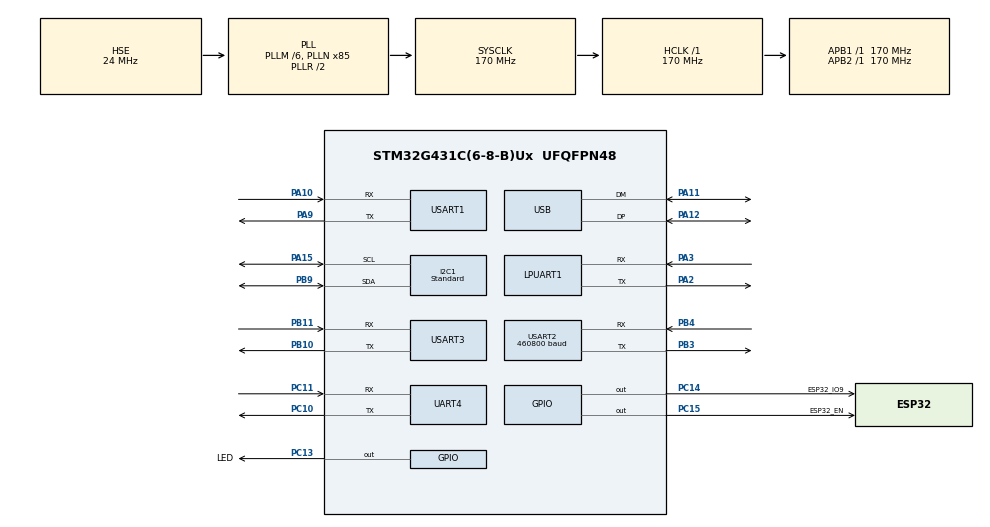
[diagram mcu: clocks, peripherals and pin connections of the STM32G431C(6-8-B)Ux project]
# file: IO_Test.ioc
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I2C1.I2C_Speed_Mode=I2C_Standard
I2C1.Timing=0x40B285C2
Mcu.Family=STM32G4
Mcu.Name=STM32G431C(6-8-B)Ux
Mcu.Package=UFQFPN48
NVIC.PriorityGroup=NVIC_PRIORITYGROUP_4
NVIC.UART4_IRQn=true\:0\:0\:false\:false\:true\:true\:true\:true
NVIC.USART2_IRQn=true\:0\:0\:false\:false\:true\:true\:true\:true
NVIC.USART3_IRQn=true\:0\:0\:false\:false\:true\:true\:true\:true
NVIC.USB_LP_IRQn=true\:0\:0\:false\:false\:true\:false\:true\:true
PA10.Mode=Asynchronous
PA10.Signal=USART1_RX
PA11.Mode=Device
PA11.Signal=USB_DM
PA12.Mode=Device
PA12.Signal=USB_DP
PA13.Mode=Serial_Wire
PA13.Signal=SYS_JTMS-SWDIO
PA14.Mode=Serial_Wire
PA14.Signal=SYS_JTCK-SWCLK
PA15.Mode=I2C
PA15.Signal=I2C1_SCL
PA2.Mode=Asynchronous
PA2.Signal=LPUART1_TX
PA3.Mode=Asynchronous
PA3.Signal=LPUART1_RX
PA9.Mode=Asynchronous
PA9.Signal=USART1_TX
PB10.Mode=Asynchronous
PB10.Signal=USART3_TX
PB11.Mode=Asynchronous
PB11.Signal=USART3_RX
PB3.Mode=Asynchronous
PB3.Signal=USART2_TX
PB4.Mode=Asynchronous
PB4.Signal=USART2_RX
PB9.Mode=I2C
PB9.Signal=I2C1_SDA
PC10.Mode=Asynchronous
PC10.Signal=UART4_TX
PC11.Mode=Asynchronous
PC11.Signal=UART4_RX
PC13.GPIO_Label=LED
PC13.Signal=GPIO_Output
PC14-OSC32_IN.GPIO_Label=ESP32_IO9
PC14-OSC32_IN.Signal=GPIO_Output
PC15-OSC32_OUT.GPIO_Label=ESP32_EN
PC15-OSC32_OUT.Signal=GPIO_Output
PF0-OSC_IN.Mode=HSE-External-Oscillator
PF0-OSC_IN.Signal=RCC_OSC_IN
PF1-OSC_OUT.Mode=HSE-External-Oscillator
PF1-OSC_OUT.Signal=RCC_OSC_OUT
ProjectManager.HeapSize=0x200
ProjectManager.StackSize=0x400
ProjectManager.TargetToolchain=MDK-ARM V5.32
RCC.ADC12Freq_Value=170000000
RCC.AHBFreq_Value=170000000
RCC.APB1Freq_Value=170000000
RCC.APB1TimFreq_Value=170000000
RCC.APB2Freq_Value=170000000
RCC.APB2TimFreq_Value=170000000
RCC.CK48CLockSelection=RCC_USBCLKSOURCE_HSI48
RCC.CortexFreq_Value=170000000
RCC.EXTERNAL_CLOCK_VALUE=12288000
RCC.HCLKFreq_Value=170000000
RCC.HSE_VALUE=24000000
RCC.HSI48_VALUE=48000000
RCC.HSI_VALUE=16000000
RCC.LSE_VALUE=32768
RCC.PLLM=RCC_PLLM_DIV6
RCC.PLLN=85
RCC.PLLSourceVirtual=RCC_PLLSOURCE_HSE
RCC.SYSCLKFreq_VALUE=170000000
RCC.SYSCLKSource=RCC_SYSCLKSOURCE_PLLCLK
RCC.USBFreq_Value=48000000
RCC.VCOOutputFreq_Value=340000000
USART1.VirtualMode-Asynchronous=VM_ASYNC
USART2.BaudRate=460800
USART2.VirtualMode-Asynchronous=VM_ASYNC
USART3.VirtualMode-Asynchronous=VM_ASYNC
USB_DEVICE.CLASS_NAME_FS=CDC
USB_DEVICE.VirtualMode=Cdc
USB_DEVICE.VirtualModeFS=Cdc_FS
VP_SYS_VS_DBSignals.Mode=DisableDeadBatterySignals
VP_USB_DEVICE_VS_USB_DEVICE_CDC_FS.Mode=CDC_FS
board=custom

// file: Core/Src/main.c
/* USER CODE BEGIN Header */
/**
  ******************************************************************************
  * @file           : main.c
  * @brief          : Main program body
  ******************************************************************************
  * @attention
  *
  * Copyright (c) 2025 STMicroelectronics.
  * All rights reserved.
  *
  * This software is licensed under terms that can be found in the LICENSE file
  * in the root directory of this software component.
  * If no LICENSE file comes with this software, it is provided AS-IS.
  *
  ******************************************************************************
  */
/* USER CODE END Header */
#include "main.h"
#include "i2c.h"
#include "usart.h"
#include "usb_device.h"
#include "gpio.h"

/* USER CODE BEGIN Includes */
#include "User_function.h"
/* USER CODE END Includes */

/* USER CODE BEGIN PV */
uint8_t CDC_Rx_Buf[256];
/* USER CODE END PV */

void SystemClock_Config(void);

int main(void)
{

  /* MCU Configuration--------------------------------------------------------*/

  /* Reset of all peripherals, Initializes the Flash interface and the Systick. */
  HAL_Init();

  /* Configure the system clock */
  SystemClock_Config();

  /* Initialize all configured peripherals */
  MX_GPIO_Init();
  MX_USB_Device_Init();
  MX_USART2_UART_Init();
  MX_USART3_UART_Init();
  MX_UART4_Init();
  MX_I2C1_Init();
  MX_LPUART1_UART_Init();
  MX_USART1_UART_Init();

  /* Infinite loop */
  /* USER CODE BEGIN WHILE */
  while (1)
  {
    if(Read_USB_CDC_Buf(CDC_Rx_Buf))
    {
        if(strstr(CDC_Rx_Buf,"��"))
        {
            HAL_UART_Transmit(&huart2,"PWM2_Duty=125,PWM3_Duty=125,PWM4_Duty=125,PWM5_Duty=125,PWM6_Duty=125",69,100);
        }
        else if(strstr(CDC_Rx_Buf,"��"))
        {
            HAL_UART_Transmit(&huart2,"PWM2_Duty=25,PWM3_Duty=25,PWM4_Duty=25,PWM5_Duty=25,PWM6_Duty=25",64,100);
        }
    }
    /* USER CODE END WHILE */

  }
}

void SystemClock_Config(void)
{
  RCC_OscInitTypeDef RCC_OscInitStruct = {0};
  RCC_ClkInitTypeDef RCC_ClkInitStruct = {0};

  /** Configure the main internal regulator output voltage
  */
  HAL_PWREx_ControlVoltageScaling(PWR_REGULATOR_VOLTAGE_SCALE1_BOOST);

  /** Initializes the RCC Oscillators according to the specified parameters
  * in the RCC_OscInitTypeDef structure.
  */
  RCC_OscInitStruct.OscillatorType = RCC_OSCILLATORTYPE_HSI48|RCC_OSCILLATORTYPE_HSE;
  RCC_OscInitStruct.HSEState = RCC_HSE_ON;
  RCC_OscInitStruct.HSI48State = RCC_HSI48_ON;
  RCC_OscInitStruct.PLL.PLLState = RCC_PLL_ON;
  RCC_OscInitStruct.PLL.PLLSource = RCC_PLLSOURCE_HSE;
  RCC_OscInitStruct.PLL.PLLM = RCC_PLLM_DIV6;
  RCC_OscInitStruct.PLL.PLLN = 85;
  RCC_OscInitStruct.PLL.PLLP = RCC_PLLP_DIV2;
  RCC_OscInitStruct.PLL.PLLQ = RCC_PLLQ_DIV2;
  RCC_OscInitStruct.PLL.PLLR = RCC_PLLR_DIV2;
  if (HAL_RCC_OscConfig(&RCC_OscInitStruct) != HAL_OK)
  {
    Error_Handler();
  }

  /** Initializes the CPU, AHB and APB buses clocks
  */
  RCC_ClkInitStruct.ClockType = RCC_CLOCKTYPE_HCLK|RCC_CLOCKTYPE_SYSCLK
                              |RCC_CLOCKTYPE_PCLK1|RCC_CLOCKTYPE_PCLK2;
  RCC_ClkInitStruct.SYSCLKSource = RCC_SYSCLKSOURCE_PLLCLK;
  RCC_ClkInitStruct.AHBCLKDivider = RCC_SYSCLK_DIV1;
  RCC_ClkInitStruct.APB1CLKDivider = RCC_HCLK_DIV1;
  RCC_ClkInitStruct.APB2CLKDivider = RCC_HCLK_DIV1;

  if (HAL_RCC_ClockConfig(&RCC_ClkInitStruct, FLASH_LATENCY_4) != HAL_OK)
  {
    Error_Handler();
  }
}

void Error_Handler(void)
{
  __disable_irq();
  while (1)
  {
  }
}
